CM_ "AUTOGENERATED FILE, DO NOT EDIT";

CM_ "chrysler_jeep_commander.dbc starts here";
"CM_ "IMPORT _stellantis_common.dbc";"

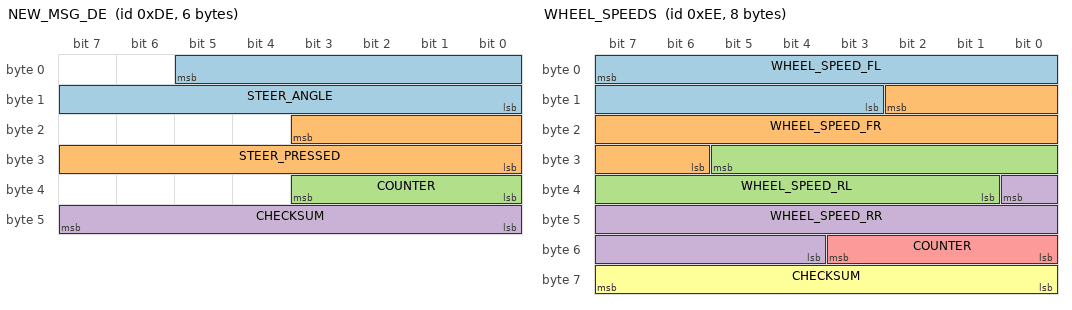
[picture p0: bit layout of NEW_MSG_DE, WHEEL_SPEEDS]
BO_ 222 NEW_MSG_DE: 6 XXX
 SG_ STEER_ANGLE : 5|14@0+ (1,0) [0|7] "" XXX
 SG_ STEER_PRESSED : 19|12@0+ (1,0) [0|8191] "" XXX
 SG_ COUNTER : 35|4@0+ (1,0) [0|15] "" XXX
 SG_ CHECKSUM : 47|8@0+ (1,0) [0|255] "" XXX

BO_ 238 WHEEL_SPEEDS: 8 XXX
 SG_ WHEEL_SPEED_FL : 7|13@0+ (0.017,0) [0|8191] "m/s" XXX
 SG_ WHEEL_SPEED_FR : 10|13@0+ (0.017,0) [0|8191] "m/s" XXX
 SG_ WHEEL_SPEED_RL : 29|13@0+ (0.017,0) [0|8191] "m/s" XXX
 SG_ WHEEL_SPEED_RR : 32|13@0+ (0.017,0) [0|8191] "m/s" XXX
 SG_ COUNTER : 51|4@0+ (1,0) [0|15] "" XXX
 SG_ CHECKSUM : 63|8@0+ (1,0) [0|255] "" XXX

BO_ 250 BRAKE_PRESSED_4: 8 XXX
 SG_ BRAKE_PRESSED_4 : 2|1@0+ (1,0) [0|1] "" XXX

BO_ 252 NEW_MSG_FC: 8 XXX
 SG_ NEW_SIGNAL_2 : 5|12@0+ (1,0) [0|2047] "" XXX
 SG_ NEW_SIGNAL_1 : 20|12@0+ (1,0) [0|127] "" XXX

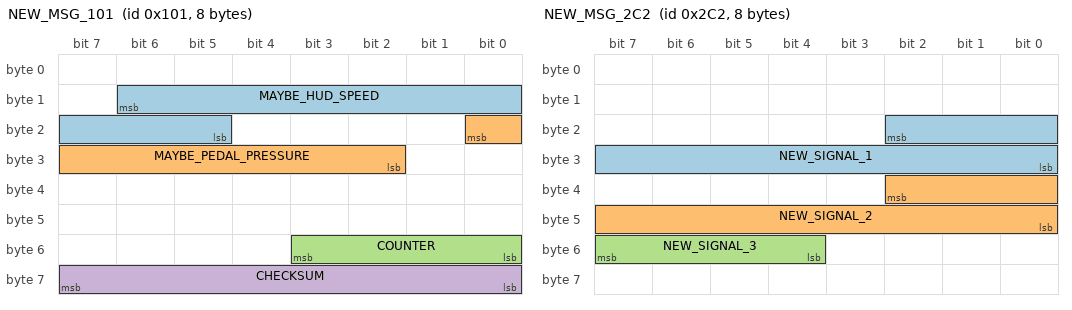
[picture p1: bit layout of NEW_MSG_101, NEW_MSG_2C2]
BO_ 257 NEW_MSG_101: 8 XXX
 SG_ MAYBE_HUD_SPEED : 14|10@0+ (1,0) [0|1023] "" XXX
 SG_ MAYBE_PEDAL_PRESSURE : 16|7@0+ (1,0) [0|127] "" XXX
 SG_ COUNTER : 51|4@0+ (1,0) [0|15] "" XXX
 SG_ CHECKSUM : 63|8@0+ (1,0) [0|255] "" XXX

BO_ 278 NEW_MSG_116: 8 XXX

BO_ 706 NEW_MSG_2C2: 8 XXX
 SG_ NEW_SIGNAL_1 : 18|11@0+ (1,0) [0|127] "" XXX
 SG_ NEW_SIGNAL_2 : 34|11@0+ (1,0) [0|2047] "" XXX
 SG_ NEW_SIGNAL_3 : 55|4@0+ (1,0) [0|15] "" XXX
